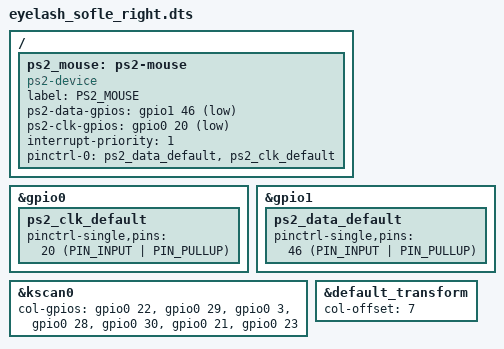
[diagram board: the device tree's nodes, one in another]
/*
*
* Copyright (c) 2021 Darryl deHaan
* SPDX-License-Identifier: MIT
*
*/
#include "eyelash_sofle.dtsi"

/ {
    ps2_mouse: ps2-mouse {
        compatible = "ps2-device";
        label = "PS2_MOUSE";

        ps2-data-gpios = <&gpio1 46 (GPIO_PULL_UP | GPIO_ACTIVE_LOW)>;
        ps2-clk-gpios  = <&gpio0 20 (GPIO_PULL_UP | GPIO_ACTIVE_LOW)>;

        interrupt-priority = <1>;

        pinctrl-0 = <&ps2_data_default &ps2_clk_default>;
        pinctrl-names = "default";
    };
};

&gpio0 {
    ps2_clk_default: ps2_clk_default {
        pinctrl-single,pins = <20 (PIN_INPUT | PIN_PULLUP)>;
    };
};

&gpio1 {
    ps2_data_default: ps2_data_default {
        pinctrl-single,pins = <46 (PIN_INPUT | PIN_PULLUP)>;
    };
};

&kscan0 {
     col-gpios
        = <&gpio0 22 GPIO_ACTIVE_HIGH>
         , <&gpio0 29 GPIO_ACTIVE_HIGH>
         , <&gpio0 3 GPIO_ACTIVE_HIGH>
         , <&gpio0 28 GPIO_ACTIVE_HIGH>
         , <&gpio0 30 GPIO_ACTIVE_HIGH>
         , <&gpio0 21 GPIO_ACTIVE_HIGH>
         , <&gpio0 23 GPIO_ACTIVE_HIGH>
         ;
};

&default_transform {
    col-offset = <7>;
};

